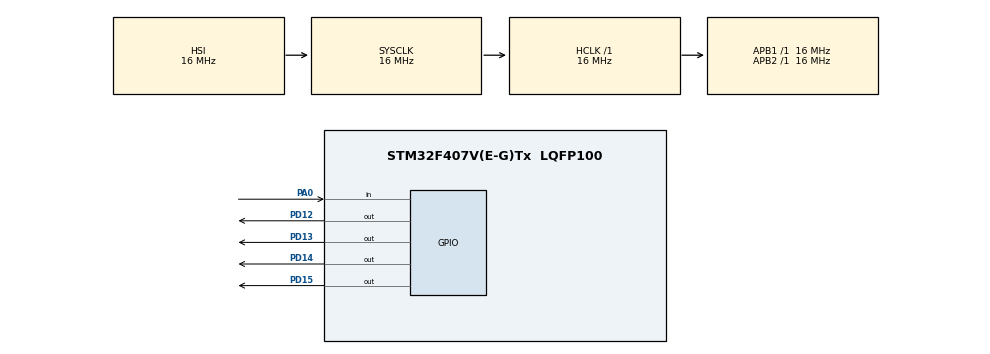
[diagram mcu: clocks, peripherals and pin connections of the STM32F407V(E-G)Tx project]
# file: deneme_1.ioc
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Mcu.Family=STM32F4
Mcu.Name=STM32F407V(E-G)Tx
Mcu.Package=LQFP100
NVIC.PriorityGroup=NVIC_PRIORITYGROUP_4
PA0-WKUP.Signal=GPIO_Input
PA13.Mode=Serial_Wire
PA13.Signal=SYS_JTMS-SWDIO
PA14.Mode=Serial_Wire
PA14.Signal=SYS_JTCK-SWCLK
PD12.Signal=GPIO_Output
PD13.Signal=GPIO_Output
PD14.Signal=GPIO_Output
PD15.Signal=GPIO_Output
ProjectManager.HeapSize=0x200
ProjectManager.StackSize=0x400
ProjectManager.TargetToolchain=MDK-ARM V5
RCC.AHBFreq_Value=16000000
RCC.APB1Freq_Value=16000000
RCC.APB2Freq_Value=16000000
RCC.CortexFreq_Value=16000000
RCC.HSE_VALUE=25000000
RCC.HSI_VALUE=16000000
RCC.LSE_VALUE=32768
RCC.SYSCLKFreq_VALUE=16000000
RCC.VCOOutputFreq_Value=192000000
TIM2.Period=9999
TIM2.Prescaler=16000-1
VP_TIM2_VS_ClockSourceINT.Mode=Internal
board=custom

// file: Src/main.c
/* USER CODE BEGIN Header */
/**
  ******************************************************************************
  * @file           : main.c
  * @brief          : Main program body
  ******************************************************************************
  ** This notice applies to any and all portions of this file
  * that are not between comment pairs USER CODE BEGIN and
  * USER CODE END. Other portions of this file, whether
  * inserted by the user or by software development tools
  * are owned by their respective copyright owners.
  *
  * COPYRIGHT(c) 2020 STMicroelectronics
  *
  * Redistribution and use in source and binary forms, with or without modification,
  * are permitted provided that the following conditions are met:
  *   1. Redistributions of source code must retain the above copyright notice,
  *      this list of conditions and the following disclaimer.
  *   2. Redistributions in binary form must reproduce the above copyright notice,
  *      this list of conditions and the following disclaimer in the documentation
  *      and/or other materials provided with the distribution.
  *   3. Neither the name of STMicroelectronics nor the names of its contributors
  *      may be used to endorse or promote products derived from this software
  *      without specific prior written permission.
  *
  * THIS SOFTWARE IS PROVIDED BY THE COPYRIGHT HOLDERS AND CONTRIBUTORS "AS IS"
  * AND ANY EXPRESS OR IMPLIED WARRANTIES, INCLUDING, BUT NOT LIMITED TO, THE
  * IMPLIED WARRANTIES OF MERCHANTABILITY AND FITNESS FOR A PARTICULAR PURPOSE ARE
  * DISCLAIMED. IN NO EVENT SHALL THE COPYRIGHT HOLDER OR CONTRIBUTORS BE LIABLE
  * FOR ANY DIRECT, INDIRECT, INCIDENTAL, SPECIAL, EXEMPLARY, OR CONSEQUENTIAL
  * DAMAGES (INCLUDING, BUT NOT LIMITED TO, PROCUREMENT OF SUBSTITUTE GOODS OR
  * SERVICES; LOSS OF USE, DATA, OR PROFITS; OR BUSINESS INTERRUPTION) HOWEVER
  * CAUSED AND ON ANY THEORY OF LIABILITY, WHETHER IN CONTRACT, STRICT LIABILITY,
  * OR TORT (INCLUDING NEGLIGENCE OR OTHERWISE) ARISING IN ANY WAY OUT OF THE USE
  * OF THIS SOFTWARE, EVEN IF ADVISED OF THE POSSIBILITY OF SUCH DAMAGE.
  *
  ******************************************************************************
  */
/* USER CODE END Header */

#include "main.h"

/* USER CODE BEGIN Includes */
uint16_t sayac=0;
/* USER CODE END Includes */

TIM_HandleTypeDef htim2;

void SystemClock_Config(void);
static void MX_GPIO_Init(void);
static void MX_TIM2_Init(void);

int main(void)
{

  /* MCU Configuration--------------------------------------------------------*/

  /* Reset of all peripherals, Initializes the Flash interface and the Systick. */
  HAL_Init();

  /* Configure the system clock */
  SystemClock_Config();

  /* Initialize all configured peripherals */
  MX_GPIO_Init();
  MX_TIM2_Init();

  /* Infinite loop */
  while (1)
  {
  while( (HAL_GPIO_ReadPin(GPIOA,GPIO_PIN_0)) !=0 )
  {

	  HAL_TIM_Base_Start(&htim2);
	  sayac= __HAL_TIM_GetCounter(&htim2);
                                                      //	  while((HAL_GPIO_ReadPin(GPIOA,GPIO_PIN_0)) !=0 )
														//	  {sayac= __HAL_TIM_GetCounter(&htim2);}
														// __HAL_TIM_SetCounter(&htim2,0);

	  while(sayac>=3099)
	  {
			while( (HAL_GPIO_ReadPin(GPIOA,GPIO_PIN_0)) !=0 );
			HAL_Delay(100);

			while( (HAL_GPIO_ReadPin(GPIOA,GPIO_PIN_0)) !=1 ) {
				HAL_GPIO_WritePin(GPIOD,GPIO_PIN_12|GPIO_PIN_13,GPIO_PIN_SET);
				HAL_Delay(500);
			 }

			if( (HAL_GPIO_ReadPin(GPIOA,GPIO_PIN_0)))
				{
					__HAL_TIM_SetCounter(&htim2,0);
					sayac= __HAL_TIM_GetCounter(&htim2);
					HAL_GPIO_WritePin(GPIOD,GPIO_PIN_12|GPIO_PIN_13,GPIO_PIN_RESET);
				}
	  }

  }

  HAL_Delay(200);

  if( (HAL_GPIO_ReadPin(GPIOA,GPIO_PIN_0)) )
    __HAL_TIM_SetCounter(&htim2,0);
//
//    /* USER CODE BEGIN 3 */
  }
  /* USER CODE END 3 */
}

void SystemClock_Config(void)
{
  RCC_OscInitTypeDef RCC_OscInitStruct = {0};
  RCC_ClkInitTypeDef RCC_ClkInitStruct = {0};

  /**Configure the main internal regulator output voltage
  */
  __HAL_RCC_PWR_CLK_ENABLE();
  __HAL_PWR_VOLTAGESCALING_CONFIG(PWR_REGULATOR_VOLTAGE_SCALE1);
  /**Initializes the CPU, AHB and APB busses clocks
  */
  RCC_OscInitStruct.OscillatorType = RCC_OSCILLATORTYPE_HSI;
  RCC_OscInitStruct.HSIState = RCC_HSI_ON;
  RCC_OscInitStruct.HSICalibrationValue = RCC_HSICALIBRATION_DEFAULT;
  RCC_OscInitStruct.PLL.PLLState = RCC_PLL_NONE;
  if (HAL_RCC_OscConfig(&RCC_OscInitStruct) != HAL_OK)
  {
    Error_Handler();
  }
  /**Initializes the CPU, AHB and APB busses clocks
  */
  RCC_ClkInitStruct.ClockType = RCC_CLOCKTYPE_HCLK|RCC_CLOCKTYPE_SYSCLK
                              |RCC_CLOCKTYPE_PCLK1|RCC_CLOCKTYPE_PCLK2;
  RCC_ClkInitStruct.SYSCLKSource = RCC_SYSCLKSOURCE_HSI;
  RCC_ClkInitStruct.AHBCLKDivider = RCC_SYSCLK_DIV1;
  RCC_ClkInitStruct.APB1CLKDivider = RCC_HCLK_DIV1;
  RCC_ClkInitStruct.APB2CLKDivider = RCC_HCLK_DIV1;

  if (HAL_RCC_ClockConfig(&RCC_ClkInitStruct, FLASH_LATENCY_0) != HAL_OK)
  {
    Error_Handler();
  }
}

static void MX_TIM2_Init(void)
{

  TIM_ClockConfigTypeDef sClockSourceConfig = {0};
  TIM_MasterConfigTypeDef sMasterConfig = {0};

  htim2.Instance = TIM2;
  htim2.Init.Prescaler = 16000-1;
  htim2.Init.CounterMode = TIM_COUNTERMODE_UP;
  htim2.Init.Period = 9999;
  htim2.Init.ClockDivision = TIM_CLOCKDIVISION_DIV1;
  if (HAL_TIM_Base_Init(&htim2) != HAL_OK)
  {
    Error_Handler();
  }
  sClockSourceConfig.ClockSource = TIM_CLOCKSOURCE_INTERNAL;
  if (HAL_TIM_ConfigClockSource(&htim2, &sClockSourceConfig) != HAL_OK)
  {
    Error_Handler();
  }
  sMasterConfig.MasterOutputTrigger = TIM_TRGO_RESET;
  sMasterConfig.MasterSlaveMode = TIM_MASTERSLAVEMODE_DISABLE;
  if (HAL_TIMEx_MasterConfigSynchronization(&htim2, &sMasterConfig) != HAL_OK)
  {
    Error_Handler();
  }

}

static void MX_GPIO_Init(void)
{
  GPIO_InitTypeDef GPIO_InitStruct = {0};

  /* GPIO Ports Clock Enable */
  __HAL_RCC_GPIOA_CLK_ENABLE();
  __HAL_RCC_GPIOD_CLK_ENABLE();

  /*Configure GPIO pin Output Level */
  HAL_GPIO_WritePin(GPIOD, GPIO_PIN_12|GPIO_PIN_13|GPIO_PIN_14|GPIO_PIN_15, GPIO_PIN_RESET);

  /*Configure GPIO pin : PA0 */
  GPIO_InitStruct.Pin = GPIO_PIN_0;
  GPIO_InitStruct.Mode = GPIO_MODE_INPUT;
  GPIO_InitStruct.Pull = GPIO_NOPULL;
  HAL_GPIO_Init(GPIOA, &GPIO_InitStruct);

  /*Configure GPIO pins : PD12 PD13 PD14 PD15 */
  GPIO_InitStruct.Pin = GPIO_PIN_12|GPIO_PIN_13|GPIO_PIN_14|GPIO_PIN_15;
  GPIO_InitStruct.Mode = GPIO_MODE_OUTPUT_PP;
  GPIO_InitStruct.Pull = GPIO_NOPULL;
  GPIO_InitStruct.Speed = GPIO_SPEED_FREQ_LOW;
  HAL_GPIO_Init(GPIOD, &GPIO_InitStruct);

}

void Error_Handler(void)
{
}

/************************ (C) COPYRIGHT STMicroelectronics *****END OF FILE****/
